# earlgrey register map
Vendor: lowRISC; File version: 0.1
CPU: ibex rev01, little endian, no MPU, no FPU, VTOR, 2 interrupt priority bits, 2 interrupts
Registers are 32-bit, read-write, no defined reset value unless marked. A register's access mark holds for its fields unless they carry their own. Offsets are from the block's base; [hi:lo] are bit positions; {n}, {i} and the like mark numbered series.

## HMAC — Accelerator for SHA-256-based keyed hash message authentication code and the SHA-256 hash function
Base 0x41110000
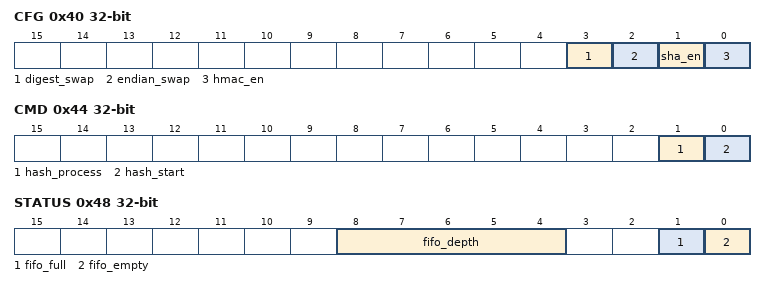
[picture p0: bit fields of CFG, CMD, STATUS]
0x40 CFG — HMAC Configuration register.The register is updated when the engine is in Idle.If the software updates the register while the engine computes the hash,the updated value is discarded.
  [3] digest_swap — Digest register byte swap.If 1 the value contained in each digest output register isconverted to big-endian byte order.This setting does not affect the order of the digest outputregisters, !!DIGEST_0 still contains the first 4 bytes ofthe digest.
  [2] endian_swap — Endian swap.If 0, each value will be added to the message in little-endianbyte order. The value is written to MSG_FIFO same to the SW writes.If 1, then each individual multi-byte value, regardless of itsalignment, written to !!MSG_FIFO will be added to the messagein big-endian byte order.A message written to !!MSG_FIFO one byte at a time will not beaffected by this setting.From a hardware perspective byte swaps are performed on a TL-ULword granularity.
  [1] sha_en — SHA256 enable. If 0, SHA engine won't initiate compression,this is used to stop operation of the SHA engine until configurationhas been done. When the SHA engine is disabled the digest is cleared.
  [0] hmac_en — HMAC datapath enable.If this bit is 1, HMAC operates when `hash_start` toggles.
0x44 CMD — HMAC command register
  [1] hash_process — If writes 1 into this field, SHA256 or HMAC calculates the digest or signingbased on currently received message.
  [0] hash_start — If writes 1 into this field, SHA256 or HMAC begins its operation.CPU should configure relative information first, such as message_length,secret_key.
0x48 STATUS ro — HMAC Status register
  [8:4] fifo_depth — FIFO entry count.
  [1] fifo_full — FIFO full. Data written to the FIFO whilst it is full will cause back-pressure on the interconnect
  [0] fifo_empty
0x4C ERR_CODE ro — HMAC Error Code
  [31:0] err_code — If error interrupt occurs, this register has information of error cause.Please take a look at `hw/ip/hmac/rtl/hmac_pkg.sv:err_code_e enum type.
0x50 WIPE_SECRET wo — Randomize internal secret registers.If CPU writes value into the register, the value is used to randomize internalvariables such as secret key, internal state machine, or hash value.
  [31:0] secret — Secret value
0x54 KEY_0 wo — HMAC Secret KeySHA256 assumes secret key is hashed 256bit key.Order of the secret key is:key[255:0] = {KEY0, KEY1, KEY2, ... , KEY7};The registers are allowed to be updated when the engine is in Idle state.If the engine computes the hash, it discards any attempts to update the secret keysand report an error.
  [31:0] key_0 — 32-bit chunk of 256-bit Secret Key
0x58 KEY_1 wo — HMAC Secret KeySHA256 assumes secret key is hashed 256bit key.Order of the secret key is:key[255:0] = {KEY0, KEY1, KEY2, ... , KEY7};The registers are allowed to be updated when the engine is in Idle state.If the engine computes the hash, it discards any attempts to update the secret keysand report an error.
  [31:0] key_1 — 32-bit chunk of 256-bit Secret Key
0x5C KEY_2 wo — HMAC Secret KeySHA256 assumes secret key is hashed 256bit key.Order of the secret key is:key[255:0] = {KEY0, KEY1, KEY2, ... , KEY7};The registers are allowed to be updated when the engine is in Idle state.If the engine computes the hash, it discards any attempts to update the secret keysand report an error.
  [31:0] key_2 — 32-bit chunk of 256-bit Secret Key
0x60 KEY_3 wo — HMAC Secret KeySHA256 assumes secret key is hashed 256bit key.Order of the secret key is:key[255:0] = {KEY0, KEY1, KEY2, ... , KEY7};The registers are allowed to be updated when the engine is in Idle state.If the engine computes the hash, it discards any attempts to update the secret keysand report an error.
  [31:0] key_3 — 32-bit chunk of 256-bit Secret Key
0x64 KEY_4 wo — HMAC Secret KeySHA256 assumes secret key is hashed 256bit key.Order of the secret key is:key[255:0] = {KEY0, KEY1, KEY2, ... , KEY7};The registers are allowed to be updated when the engine is in Idle state.If the engine computes the hash, it discards any attempts to update the secret keysand report an error.
  [31:0] key_4 — 32-bit chunk of 256-bit Secret Key
0x68 KEY_5 wo — HMAC Secret KeySHA256 assumes secret key is hashed 256bit key.Order of the secret key is:key[255:0] = {KEY0, KEY1, KEY2, ... , KEY7};The registers are allowed to be updated when the engine is in Idle state.If the engine computes the hash, it discards any attempts to update the secret keysand report an error.
  [31:0] key_5 — 32-bit chunk of 256-bit Secret Key
0x6C KEY_6 wo — HMAC Secret KeySHA256 assumes secret key is hashed 256bit key.Order of the secret key is:key[255:0] = {KEY0, KEY1, KEY2, ... , KEY7};The registers are allowed to be updated when the engine is in Idle state.If the engine computes the hash, it discards any attempts to update the secret keysand report an error.
  [31:0] key_6 — 32-bit chunk of 256-bit Secret Key
0x70 KEY_7 wo — HMAC Secret KeySHA256 assumes secret key is hashed 256bit key.Order of the secret key is:key[255:0] = {KEY0, KEY1, KEY2, ... , KEY7};The registers are allowed to be updated when the engine is in Idle state.If the engine computes the hash, it discards any attempts to update the secret keysand report an error.
  [31:0] key_7 — 32-bit chunk of 256-bit Secret Key
0x74 DIGEST_0 ro — Digest output. If HMAC is disabled, the register shows result of SHA256 Order of the digest is: digest[255:0] = {DIGEST0, DIGEST1, DIGEST2, ... , DIGEST7};
  [31:0] digest_0 — 32-bit chunk of 256-bit Digest
0x78 DIGEST_1 ro — Digest output. If HMAC is disabled, the register shows result of SHA256 Order of the digest is: digest[255:0] = {DIGEST0, DIGEST1, DIGEST2, ... , DIGEST7};
  [31:0] digest_1 — 32-bit chunk of 256-bit Digest
0x7C DIGEST_2 ro — Digest output. If HMAC is disabled, the register shows result of SHA256 Order of the digest is: digest[255:0] = {DIGEST0, DIGEST1, DIGEST2, ... , DIGEST7};
  [31:0] digest_2 — 32-bit chunk of 256-bit Digest
0x80 DIGEST_3 ro — Digest output. If HMAC is disabled, the register shows result of SHA256 Order of the digest is: digest[255:0] = {DIGEST0, DIGEST1, DIGEST2, ... , DIGEST7};
  [31:0] digest_3 — 32-bit chunk of 256-bit Digest
0x84 DIGEST_4 ro — Digest output. If HMAC is disabled, the register shows result of SHA256 Order of the digest is: digest[255:0] = {DIGEST0, DIGEST1, DIGEST2, ... , DIGEST7};
  [31:0] digest_4 — 32-bit chunk of 256-bit Digest
0x88 DIGEST_5 ro — Digest output. If HMAC is disabled, the register shows result of SHA256 Order of the digest is: digest[255:0] = {DIGEST0, DIGEST1, DIGEST2, ... , DIGEST7};
  [31:0] digest_5 — 32-bit chunk of 256-bit Digest
0x8C DIGEST_6 ro — Digest output. If HMAC is disabled, the register shows result of SHA256 Order of the digest is: digest[255:0] = {DIGEST0, DIGEST1, DIGEST2, ... , DIGEST7};
  [31:0] digest_6 — 32-bit chunk of 256-bit Digest
0x90 DIGEST_7 ro — Digest output. If HMAC is disabled, the register shows result of SHA256 Order of the digest is: digest[255:0] = {DIGEST0, DIGEST1, DIGEST2, ... , DIGEST7};
  [31:0] digest_7 — 32-bit chunk of 256-bit Digest
0x94 MSG_LENGTH_LOWER ro — Received Message Length calculated by the HMAC in bits [31:0]Message is byte granularity.lower 3bits [2:0] are ignored.
  [31:0] v — Message Length [31:0]
0x98 MSG_LENGTH_UPPER ro — Received Message Length calculated by the HMAC in bits [63:32]
  [31:0] v — Message Length [63:32]
